# RP2350 register map
Vendor: Raspberry Pi; Series: RP; File version: 0.1
CPU: CM33 r1p0, little endian, MPU, FPU, DSP, VTOR, 4 interrupt priority bits, 52 interrupts, 8 SAU regions
Registers are 32-bit, read-write, reset 0x0 unless marked. A register's access mark holds for its fields unless they carry their own. Offsets are from the block's base; [hi:lo] are bit positions; {n}, {i} and the like mark numbered series; 'fields as' and 'values as' point back to an identical list.

## RESETS — Peripheral description
Base 0x40020000
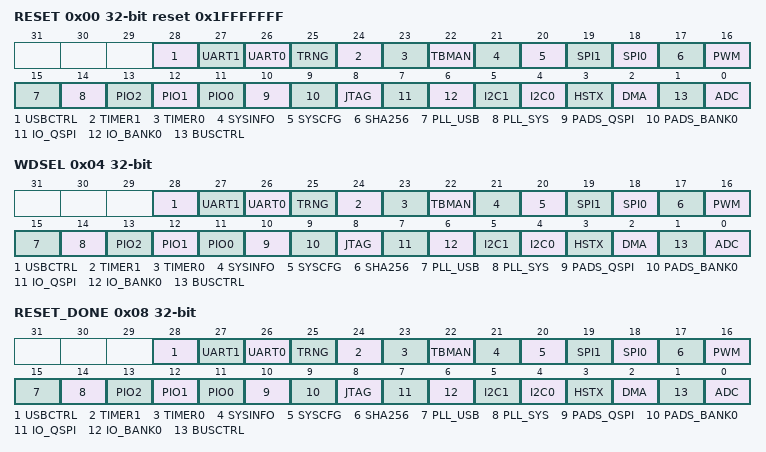
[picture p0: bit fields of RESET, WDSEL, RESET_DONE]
0x00 RESET reset 0x1FFFFFFF — register description
  [28] USBCTRL — Pre-defined description
  [27] UART1 — Pre-defined description
  [26] UART0 — Pre-defined description
  [25] TRNG — Pre-defined description
  [24] TIMER1 — Pre-defined description
  [23] TIMER0 — Pre-defined description
  [22] TBMAN — Pre-defined description
  [21] SYSINFO — Pre-defined description
  [20] SYSCFG — Pre-defined description
  [19] SPI1 — Pre-defined description
  [18] SPI0 — Pre-defined description
  [17] SHA256 — Pre-defined description
  [16] PWM — Pre-defined description
  [15] PLL_USB — Pre-defined description
  [14] PLL_SYS — Pre-defined description
  [13] PIO2 — Pre-defined description
  [12] PIO1 — Pre-defined description
  [11] PIO0 — Pre-defined description
  [10] PADS_QSPI — Pre-defined description
  [9] PADS_BANK0 — Pre-defined description
  [8] JTAG — Pre-defined description
  [7] IO_QSPI — Pre-defined description
  [6] IO_BANK0 — Pre-defined description
  [5] I2C1 — Pre-defined description
  [4] I2C0 — Pre-defined description
  [3] HSTX — Pre-defined description
  [2] DMA — Pre-defined description
  [1] BUSCTRL — Pre-defined description
  [0] ADC — Pre-defined description
0x04 WDSEL — register description
  fields as RESET
0x08 RESET_DONE — register description
  [28] USBCTRL ro — Pre-defined description
  [27] UART1 ro — Pre-defined description
  [26] UART0 ro — Pre-defined description
  [25] TRNG ro — Pre-defined description
  [24] TIMER1 ro — Pre-defined description
  [23] TIMER0 ro — Pre-defined description
  [22] TBMAN ro — Pre-defined description
  [21] SYSINFO ro — Pre-defined description
  [20] SYSCFG ro — Pre-defined description
  [19] SPI1 ro — Pre-defined description
  [18] SPI0 ro — Pre-defined description
  [17] SHA256 ro — Pre-defined description
  [16] PWM ro — Pre-defined description
  [15] PLL_USB ro — Pre-defined description
  [14] PLL_SYS ro — Pre-defined description
  [13] PIO2 ro — Pre-defined description
  [12] PIO1 ro — Pre-defined description
  [11] PIO0 ro — Pre-defined description
  [10] PADS_QSPI ro — Pre-defined description
  [9] PADS_BANK0 ro — Pre-defined description
  [8] JTAG ro — Pre-defined description
  [7] IO_QSPI ro — Pre-defined description
  [6] IO_BANK0 ro — Pre-defined description
  [5] I2C1 ro — Pre-defined description
  [4] I2C0 ro — Pre-defined description
  [3] HSTX ro — Pre-defined description
  [2] DMA ro — Pre-defined description
  [1] BUSCTRL ro — Pre-defined description
  [0] ADC ro — Pre-defined description

## PSM — Peripheral description
Base 0x40018000
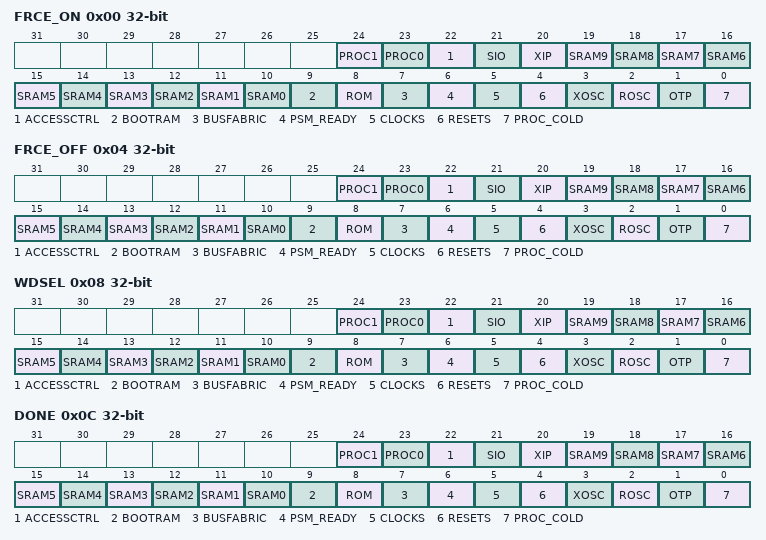
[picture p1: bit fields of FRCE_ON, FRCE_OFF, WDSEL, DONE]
0x00 FRCE_ON — Force block out of reset (i.e. power it on)
  [24] PROC1 — Pre-defined description
  [23] PROC0 — Pre-defined description
  [22] ACCESSCTRL — Pre-defined description
  [21] SIO — Pre-defined description
  [20] XIP — Pre-defined description
  [n+10] SRAM{n} (n=0..9) — Pre-defined description
  [9] BOOTRAM — Pre-defined description
  [8] ROM — Pre-defined description
  [7] BUSFABRIC — Pre-defined description
  [6] PSM_READY — Pre-defined description
  [5] CLOCKS — Pre-defined description
  [4] RESETS — Pre-defined description
  [3] XOSC — Pre-defined description
  [2] ROSC — Pre-defined description
  [1] OTP — Pre-defined description
  [0] PROC_COLD — Pre-defined description
0x04 FRCE_OFF — Force into reset (i.e. power it off)
  fields as FRCE_ON
0x08 WDSEL — Set to 1 if the watchdog should reset this
  fields as FRCE_ON
0x0C DONE — Is the subsystem ready?
  [24] PROC1 ro — Pre-defined description
  [23] PROC0 ro — Pre-defined description
  [22] ACCESSCTRL ro — Pre-defined description
  [21] SIO ro — Pre-defined description
  [20] XIP ro — Pre-defined description
  [n+10] SRAM{n} ro (n=0..9) — Pre-defined description
  [9] BOOTRAM ro — Pre-defined description
  [8] ROM ro — Pre-defined description
  [7] BUSFABRIC ro — Pre-defined description
  [6] PSM_READY ro — Pre-defined description
  [5] CLOCKS ro — Pre-defined description
  [4] RESETS ro — Pre-defined description
  [3] XOSC ro — Pre-defined description
  [2] ROSC ro — Pre-defined description
  [1] OTP ro — Pre-defined description
  [0] PROC_COLD ro — Pre-defined description
